VERSION ""

NS_ :

BS_:

BU_: ABS ESP ECU TCU SAS

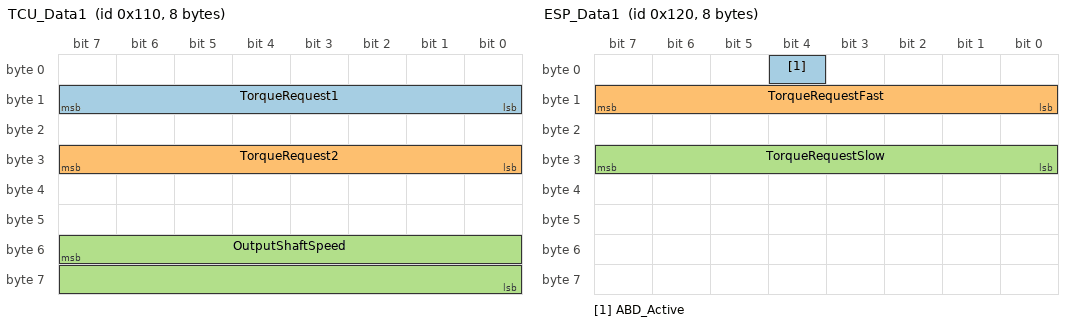
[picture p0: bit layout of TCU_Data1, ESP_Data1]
BO_ 272 TCU_Data1: 8 TCU
 SG_ TorqueRequest1 : 15|8@0+ (1,0) [0|255] ""  ABS,ESP,ECU
 SG_ TorqueRequest2 : 31|8@0+ (1,0) [0|255] ""  ABS,ESP,ECU
 SG_ OutputShaftSpeed : 55|16@0+ (1,0) [0|65535] "rpm"  ABS,ESP,ECU

BO_ 288 ESP_Data1: 8 ESP
 SG_ ABD_Active : 4|1@0+ (1,0) [0|1] "yes/no"  ECU,TCU
 SG_ TorqueRequestFast : 15|8@0+ (1,0) [0|255] ""  ECU,TCU
 SG_ TorqueRequestSlow : 31|8@0+ (1,0) [0|255] ""  ECU,TCU

BO_ 384 SAS_Data: 8 SAS
 SG_ SteeringAngle : 0|16@1- (0.1,0) [-3276.8|3276.7] "yes/no"  ECU,TCU
 SG_ SteeringSpeed : 16|8@1+ (1,0) [0|255] ""  ECU,TCU

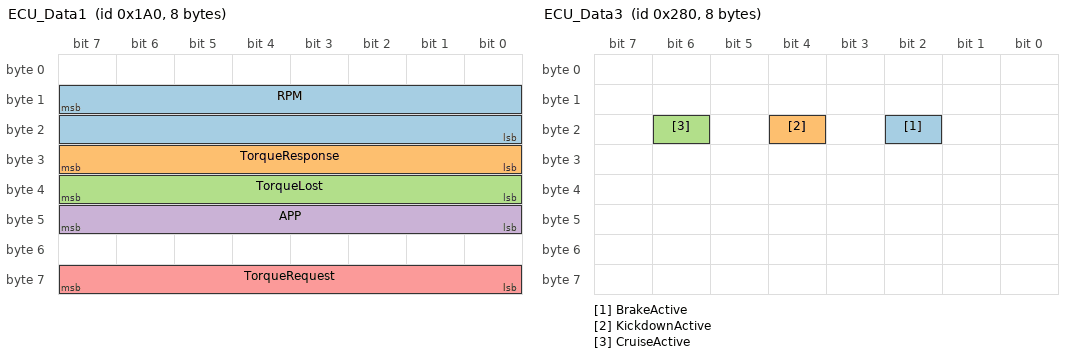
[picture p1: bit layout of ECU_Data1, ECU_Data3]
BO_ 416 ECU_Data1: 8 ECU
 SG_ RPM : 15|16@0+ (1,0) [0|65535] "rpm"  ABS,ESP,TCU
 SG_ TorqueResponse : 31|8@0+ (1,0) [0|255] ""  ABS,ESP,TCU
 SG_ TorqueLost : 39|8@0+ (1,0) [0|255] ""  ABS,ESP,TCU
 SG_ APP : 47|8@0+ (1,0) [0|102] ""  ABS,ESP,TCU
 SG_ TorqueRequest : 63|8@0+ (1,0) [0|255] ""  ABS,ESP,TCU

BO_ 448 ECU_Data2: 8 ECU
 SG_ TPS : 23|8@0+ (1,0) [0|100] ""  ABS,ESP,TCU

BO_ 640 ECU_Data3: 8 ECU
 SG_ BrakeActive : 18|1@0+ (1,0) [0|1] "yes/no"  ABS,ESP,TCU
 SG_ KickdownActive : 20|1@0+ (1,0) [0|1] "yes/no"  ABS,ESP,TCU
 SG_ CruiseActive : 22|1@0+ (1,0) [0|1] "yes/no"  ABS,ESP,TCU

BO_ 736 TCU_Data2: 8 TCU
 SG_ TOT : 31|8@0- (1,-40) [-40|215] ""  ECU
 SG_ InputShaftSpeed : 47|16@0+ (1,0) [0|65535] "rpm"  ECU

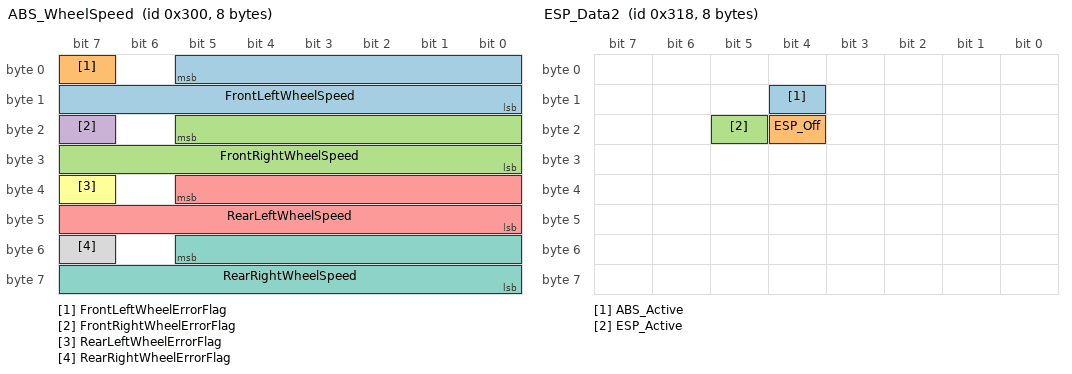
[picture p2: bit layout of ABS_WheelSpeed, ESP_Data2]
BO_ 768 ABS_WheelSpeed: 8 ABS
 SG_ FrontLeftWheelSpeed : 5|14@0+ (0.112,0) [0|255] "km/h"  ECU,TCU
 SG_ FrontLeftWheelErrorFlag : 7|1@0+ (1,0) [0|1] ""  ECU,TCU
 SG_ FrontRightWheelSpeed : 21|14@0+ (0.112,0) [0|255] "km/h"  ECU,TCU
 SG_ FrontRightWheelErrorFlag : 23|1@0+ (1,0) [0|1] ""  ECU,TCU
 SG_ RearLeftWheelSpeed : 37|14@0+ (0.112,0) [0|255] "km/h"  ECU,TCU
 SG_ RearLeftWheelErrorFlag : 39|1@0+ (1,0) [0|1] ""  ECU,TCU
 SG_ RearRightWheelSpeed : 53|14@0+ (0.112,0) [0|255] "km/h"  ECU,TCU
 SG_ RearRightWheelErrorFlag : 55|1@0+ (1,0) [0|1] ""  ECU,TCU

BO_ 792 ESP_Data2: 8 ESP
 SG_ ABS_Active : 12|1@0+ (1,0) [0|1] "yes/no"  ECU,TCU
 SG_ ESP_Off : 20|1@0+ (1,0) [0|1] "yes/no"  ECU,TCU
 SG_ ESP_Active : 21|1@0+ (1,0) [0|1] "yes/no"  ECU,TCU

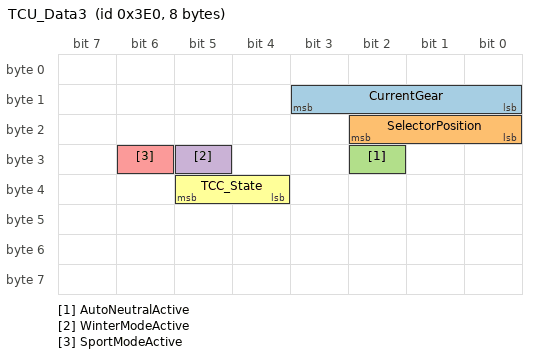
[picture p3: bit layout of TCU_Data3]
BO_ 992 TCU_Data3: 8 TCU
 SG_ CurrentGear : 11|4@0+ (1,0) [0|15] ""  ECU
 SG_ SelectorPosition : 18|3@0+ (1,0) [0|7] ""  ECU
 SG_ AutoNeutralActive : 26|1@0+ (1,0) [0|1] "yes/no"  ECU
 SG_ WinterModeActive : 29|1@0+ (1,0) [0|1] "yes/no"  ECU
 SG_ SportModeActive : 30|1@0+ (1,0) [0|1] "yes/no"  ECU
 SG_ TCC_State : 37|2@0+ (1,0) [0|2] ""  ECU

BO_ 1472 ECU_Data4: 8 ECU
 SG_ ECT : 15|8@0- (1,-40) [-40|215] ""  TCU
 SG_ IAT : 47|8@0- (1,-40) [-40|215] ""  TCU

VAL_ 992 CurrentGear 5 "1" 6 "2" 7 "3" 8 "4" ;
VAL_ 992 SelectorPosition 1 "P" 2 "R" 3 "N" 4 "D" 7 "3" 6 "2" 5 "1" ;
VAL_ 992 TCC_State 0 "Off" 1 "Partially Locked" 2 "Locked" ;
